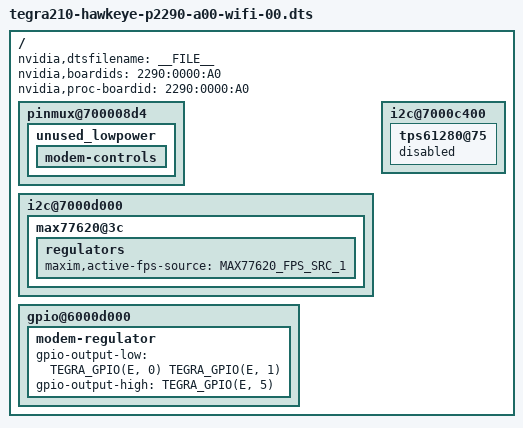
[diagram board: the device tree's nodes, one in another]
/*
 * tegra210-hawkeye-p2290-a00-wifi-00.dts: For wifi sku.
 *
 * Copyright (c) 2014-2016, NVIDIA CORPORATION.  All rights reserved.
 *
 * This program is free software; you can redistribute it and/or modify
 * it under the terms of the GNU General Public License as published by
 * the Free Software Foundation; version 2 of the License.
 *
 * This program is distributed in the hope that it will be useful, but WITHOUT
 * ANY WARRANTY; without even the implied warranty of MERCHANTABILITY or
 * FITNESS FOR A PARTICULAR PURPOSE.  See the GNU General Public License for
 * more details.
 */

#include "tegra210-hawkeye-p2290-a00-00.dts"
#include "tegra210-platforms/tegra210-sysedp.dtsi"

/ {
	nvidia,dtsfilename = __FILE__;
	nvidia,boardids = "2290:0000:A0";
	nvidia,proc-boardid = "2290:0000:A0";

	pinmux@700008d4 {
		unused_lowpower {
			modem-controls {
				status = "okay";
			};
		};
	};

	i2c@7000d000 {
		max77620@3c {
			regulators {
				maxim,active-fps-source = <MAX77620_FPS_SRC_1>;
				/delete-property/ maxim,shutdown-fps-source;
			};
		};
	};

	i2c@7000c400 {
		tps61280@75 {
			status = "disabled";
		};
	};

	gpio@6000d000 {
		modem-regulator {
			gpio-output-low = <TEGRA_GPIO(E, 0)
					   TEGRA_GPIO(E, 1)>;
			gpio-output-high = <TEGRA_GPIO(E, 5)>;
		};
	};
};
